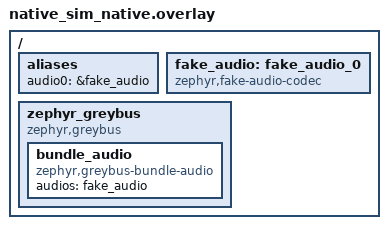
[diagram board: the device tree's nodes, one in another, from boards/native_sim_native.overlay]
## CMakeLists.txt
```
cmake_minimum_required(VERSION 3.20.0)
find_package(Zephyr REQUIRED HINTS $ENV{ZEPHYR_BASE})

set(DTS_ROOT ${CMAKE_CURRENT_SOURCE_DIR})
project(fake_audio_test)

get_filename_component(GB_ROOT ${CMAKE_CURRENT_SOURCE_DIR}/../../../.. ABSOLUTE)
target_include_directories(app PRIVATE 
  ${GB_ROOT}/drivers/audio
  ${GB_ROOT}/subsys/greybus
)

target_sources(app PRIVATE
  src/main.c 
  src/test_protocol.c
  ${GB_ROOT}/drivers/audio/fake_audio.c 
)
```

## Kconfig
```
source "Kconfig.zephyr"
rsource "../../../../drivers/audio/Kconfig"
```

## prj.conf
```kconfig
CONFIG_ZTEST=y
CONFIG_LOG=y
CONFIG_GREYBUS=y
CONFIG_GREYBUS_LOG_LEVEL_DBG=y 
CONFIG_GREYBUS_AUDIO=y
CONFIG_AUDIO=y
CONFIG_AUDIO_CODEC=y
CONFIG_FAKE_AUDIO=y
```

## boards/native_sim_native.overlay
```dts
/ {
    aliases {
        audio0 = &fake_audio;
    };

    fake_audio: fake_audio_0 {
        compatible = "zephyr,fake-audio-codec";
        status = "okay";
    };
    
    zephyr_greybus {
        compatible = "zephyr,greybus";
        status = "okay";
        
        bundle_audio: bundle_audio {
            compatible = "zephyr,greybus-bundle-audio";
            status = "okay";
            audios = <&fake_audio>; 
        };
    };
};
```

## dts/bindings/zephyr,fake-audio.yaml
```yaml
description: Fake Audio Codec Driver for Simulation
compatible: "zephyr,fake-audio-codec"
include: base.yaml
```

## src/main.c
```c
/*
 * Copyright (c) 2026 Pavithra C.P., BeagleBoard.org
 *
 * SPDX-License-Identifier: Apache-2.0
 */

#include <zephyr/ztest.h>
#include <zephyr/device.h>
#include <zephyr/audio/codec.h>
#include <zephyr/logging/log.h>
#include "fake_audio.h"

LOG_MODULE_REGISTER(audio_test, LOG_LEVEL_INF);

static const struct device *get_audio_dev(void)
{
    const struct device *dev = DEVICE_DT_GET(DT_NODELABEL(fake_audio));
    zassert_true(device_is_ready(dev), "The audio codec device is not ready!");
    return dev;
}

static void *audio_setup(void)
{
    get_audio_dev();
    LOG_INF("Audio Codec found and ready for testing.");
    return NULL;
}

ZTEST_SUITE(audio_tests, NULL, audio_setup, NULL, NULL, NULL);

ZTEST(audio_tests, test_codec_configure)
{
    const struct device *dev = get_audio_dev();
    struct audio_data *internal_state = dev->data;
    struct audio_codec_cfg cfg = {0};
    int ret;

    cfg.dai_type = AUDIO_DAI_TYPE_I2S;
    cfg.dai_cfg.pcm.samplerate = AUDIO_PCM_RATE_48K;

    ret = audio_codec_configure(dev, &cfg);
    zassert_equal(ret, 0, "audio_codec_configure failed");

    zassert_equal(internal_state->cfg.dai_type, AUDIO_DAI_TYPE_I2S, "DAI type not saved");
    zassert_equal(internal_state->cfg.dai_cfg.pcm.samplerate, AUDIO_PCM_RATE_48K, 
                  "Sample rate not saved");
}

ZTEST(audio_tests, test_output_volume)
{
    const struct device *dev = get_audio_dev();
    struct audio_data *internal_state = dev->data;
    audio_property_value_t val;
    int ret;

    val.vol = 75; /* Set volume to 75 -sample*/
    ret = audio_codec_set_property(dev, AUDIO_PROPERTY_OUTPUT_VOLUME, AUDIO_CHANNEL_ALL, val);
    
    zassert_equal(ret, 0, "Setting output volume failed");
    zassert_equal(internal_state->vol_out, 75, "Output volume state was not updated inside driver");
}

ZTEST(audio_tests, test_input_mute)
{
    const struct device *dev = get_audio_dev();
    struct audio_data *internal_state = dev->data;
    audio_property_value_t val;
    int ret;

    /*mute and unmute*/ 
    val.mute = true; 
    ret = audio_codec_set_property(dev, AUDIO_PROPERTY_INPUT_MUTE, AUDIO_CHANNEL_ALL, val);
    
    zassert_equal(ret, 0, "Setting input mute failed");
    zassert_true(internal_state->mute_in, "Input mute state was not updated to true");

    val.mute = false; 
    ret = audio_codec_set_property(dev, AUDIO_PROPERTY_INPUT_MUTE, AUDIO_CHANNEL_ALL, val);
    zassert_false(internal_state->mute_in, "Input mute state was not updated to false");
}

ZTEST(audio_tests, test_unsupported_property)
{
    const struct device *dev = get_audio_dev();
    audio_property_value_t val = { .vol = 0 };
    int ret;

    ret = audio_codec_set_property(dev, 9999, AUDIO_CHANNEL_ALL, val);
    zassert_equal(ret, -EINVAL, "Driver should return -EINVAL for unknown properties");
}

ZTEST(audio_tests, test_start_stop)
{
    const struct device *dev = get_audio_dev();
    struct audio_data *internal_state = dev->data;
    int ret;

    ret = audio_codec_start(dev, AUDIO_DAI_DIR_TXRX);
    zassert_equal(ret, 0, "Codec start failed");
    zassert_true(internal_state->is_started, "is_started flag not set to true");

    ret = audio_codec_stop(dev, AUDIO_DAI_DIR_TXRX);
    zassert_equal(ret, 0, "Codec stop failed");
    zassert_false(internal_state->is_started, "is_started flag not set to false");
}

ZTEST(audio_tests, test_null_api_safeguard)
{
    const struct device *dev = get_audio_dev();
    int ret;

    /* * We purposefully did not implement route_input in our fake driver. 
     * This test proves that the kernel safely catches it and returns -ENOSYS 
     * instead of causing a segmentation fault.
     */
    ret = audio_codec_route_input(dev, AUDIO_CHANNEL_ALL, 0);
    zassert_equal(ret, -ENOSYS, "Unimplemented API should return -ENOSYS");
}
```

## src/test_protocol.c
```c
/*
 * Copyright (c) 2026 Pavithra CP, BeagleBoard.org
 *
 * SPDX-License-Identifier: Apache-2.0
 */

#include "greybus/greybus_messages.h"
#include <zephyr/ztest.h>
#include <greybus/greybus.h>
#include <zephyr/kernel.h>
#include <zephyr/device.h>
#include <zephyr/sys/byteorder.h>
#include <zephyr/logging/log.h>
#include <zephyr/fff.h>
#include <greybus/greybus_protocols.h>
#include "greybus_audio.h"
#include "greybus_internal.h"

#define TEST_CPORT             4
#define TEST_CONTROL_ID_VOLUME 1

/*
 * Note- I have drv_data= {0} here to get rid
 * of the errors (declared but uninitialised). If that is not preferred,
 * I will initialise drv_data with memset(&drv_data, 0, sizeof(drv_data));
 */
ZTEST_SUITE(audio_protocol_tests, NULL, NULL, NULL, NULL, NULL);

ZTEST(audio_protocol_tests, test_audio_connection_lifecycle)
{
	struct gb_audio_driver_data drv_data = {0};

	gb_audio_driver.connected(&drv_data, TEST_CPORT);

	zassert_not_null(drv_data.dev, "Device pointer should be populated on connect");
	zassert_equal(drv_data.info.state, STATE_UNCONFIGURED,
		      "State should be STATE_UNCONFIGURED after connection");

	gb_audio_driver.disconnected(&drv_data);

	zassert_equal(drv_data.info.state, STATE_REMOVED,
		      "State should transition to STATE_REMOVED on disconnect");
}

ZTEST(audio_protocol_tests, test_audio_protocol_version)
{
	struct gb_audio_driver_data drv_data = {0};

	struct gb_message *msg = gb_message_request_alloc(0, GB_AUDIO_TYPE_PROTOCOL_VERSION, false);
	zassert_not_null(msg, "Failed to allocate message");

	msg->header.operation_id = 1;

	gb_audio_driver.connected(&drv_data, TEST_CPORT);

	gb_audio_driver.op_handler(&drv_data, msg, TEST_CPORT);

	zassert_equal(drv_data.info.state, STATE_UNCONFIGURED,
		      "Protocol Version request should not alter driver state");
}

ZTEST(audio_protocol_tests, test_audio_set_pcm_valid)
{
	struct gb_audio_driver_data drv_data = {0};

	gb_audio_driver.connected(&drv_data, TEST_CPORT);

	struct gb_message *msg = gb_message_request_alloc(sizeof(struct gb_audio_set_pcm_request),
							  GB_AUDIO_TYPE_SET_PCM, false);
	zassert_not_null(msg, "Failed to allocate SET_PCM message");

	struct gb_audio_set_pcm_request *req = (struct gb_audio_set_pcm_request *)msg->payload;
	req->rate = sys_cpu_to_le32(48000);
	req->channels = 2; // standard stereo audio- left and right
	req->sig_bits = 16;

	gb_audio_driver.op_handler(&drv_data, msg, TEST_CPORT);

	zassert_equal(drv_data.info.state, STATE_CONFIGURED,
		      "Driver should transition to STATE_CONFIGURED after valid PCM setup");
}

ZTEST(audio_protocol_tests, test_audio_set_control_volume)
{
	struct gb_audio_driver_data drv_data = {0};

	gb_audio_driver.connected(&drv_data, TEST_CPORT);

	struct gb_message *msg = gb_message_request_alloc(
		sizeof(struct gb_audio_set_control_request), GB_AUDIO_TYPE_SET_CONTROL, false);
	zassert_not_null(msg, "Failed to allocate SET_CONTROL message");

	struct gb_audio_set_control_request *req =
		(struct gb_audio_set_control_request *)msg->payload;
	req->control_id = TEST_CONTROL_ID_VOLUME;

	req->value.value.integer_value[0] = sys_cpu_to_le32(75); // arbitary value

	gb_audio_driver.op_handler(&drv_data, msg, TEST_CPORT);

	zassert_equal(drv_data.info.state, STATE_UNCONFIGURED,
		      "Driver state should remain stable after a control update");
}

ZTEST(audio_protocol_tests, test_audio_get_topology_size)
{
	struct gb_audio_driver_data drv_data = {0};

	gb_audio_driver.connected(&drv_data, TEST_CPORT);

	struct gb_message *msg =
		gb_message_request_alloc(0, GB_AUDIO_TYPE_GET_TOPOLOGY_SIZE, false);
	zassert_not_null(msg, "Failed to allocate GET_TOPOLOGY_SIZE message");

	gb_audio_driver.op_handler(&drv_data, msg, TEST_CPORT);

	zassert_equal(drv_data.info.state, STATE_UNCONFIGURED,
		      "Driver state should remain STATE_UNCONFIGURED after topology size query");
}

ZTEST(audio_protocol_tests, test_audio_get_topology)
{
	struct gb_audio_driver_data drv_data = {0};

	gb_audio_driver.connected(&drv_data, TEST_CPORT);

	struct gb_message *msg = gb_message_request_alloc(0, GB_AUDIO_TYPE_GET_TOPOLOGY, false);
	zassert_not_null(msg, "Failed to allocate GET_TOPOLOGY message");

	gb_audio_driver.op_handler(&drv_data, msg, TEST_CPORT);

	zassert_equal(drv_data.info.state, STATE_UNCONFIGURED,
		      "Driver state should remain STATE_UNCONFIGURED after topology query");
}

/*
 * Here the state is STATE_UNCONFIGURED by default upon connection
 * and it should remain unconfigured as it is an invalid command
 */
ZTEST(audio_protocol_tests, test_audio_activate_tx_unconfigured)
{
	struct gb_audio_driver_data drv_data = {0};
	gb_audio_driver.connected(&drv_data, TEST_CPORT);

	struct gb_message *msg = gb_message_request_alloc(0, GB_AUDIO_TYPE_ACTIVATE_TX, false);
	zassert_not_null(msg, "Failed to allocate ACTIVATE_TX message");

	gb_audio_driver.op_handler(&drv_data, msg, TEST_CPORT);

	zassert_equal(drv_data.info.state, STATE_UNCONFIGURED,
		      "State should not change on invalid TX activation");
}

ZTEST(audio_protocol_tests, test_audio_activate_tx_configured)
{
	struct gb_audio_driver_data drv_data = {0};
	gb_audio_driver.connected(&drv_data, TEST_CPORT);

	drv_data.info.state = STATE_CONFIGURED;

	struct gb_message *msg = gb_message_request_alloc(0, GB_AUDIO_TYPE_ACTIVATE_TX, false);
	zassert_not_null(msg, "Failed to allocate ACTIVATE_TX message");

	gb_audio_driver.op_handler(&drv_data, msg, TEST_CPORT);

	zassert_equal(drv_data.info.state, STATE_CONFIGURED,
		      "State should remain STATE_CONFIGURED after valid TX activation");
}

ZTEST(audio_protocol_tests, test_audio_send_data_unconfigured)
{
	struct gb_audio_driver_data drv_data = {0};
	gb_audio_driver.connected(&drv_data, TEST_CPORT);

	struct gb_message *msg = gb_message_request_alloc(
		sizeof(struct gb_audio_send_data_request) + 64, GB_AUDIO_TYPE_SEND_DATA, false);
	zassert_not_null(msg, "Failed to allocate SEND_DATA message");

	gb_audio_driver.op_handler(&drv_data, msg, TEST_CPORT);

	zassert_equal(drv_data.info.state, STATE_UNCONFIGURED,
		      "State should remain STATE_UNCONFIGURED after rejecting SEND_DATA");
}

ZTEST(audio_protocol_tests, test_audio_send_data_configured)
{
	struct gb_audio_driver_data drv_data = {0};
	gb_audio_driver.connected(&drv_data, TEST_CPORT);

	drv_data.info.state = STATE_CONFIGURED;

	struct gb_message *msg = gb_message_request_alloc(
		sizeof(struct gb_audio_send_data_request) + 128, GB_AUDIO_TYPE_SEND_DATA, false);
	zassert_not_null(msg, "Failed to allocate SEND_DATA message");

	gb_audio_driver.op_handler(&drv_data, msg, TEST_CPORT);

	zassert_equal(drv_data.info.state, STATE_CONFIGURED,
		      "State should remain STATE_CONFIGURED after successful SEND_DATA");
}

ZTEST(audio_protocol_tests, test_audio_deactivate_tx)
{
	struct gb_audio_driver_data drv_data = {0};
	gb_audio_driver.connected(&drv_data, TEST_CPORT);

	drv_data.info.state = STATE_CONFIGURED;

	struct gb_message *msg = gb_message_request_alloc(
		sizeof(struct gb_audio_deactivate_tx_request), GB_AUDIO_TYPE_DEACTIVATE_TX, false);
	zassert_not_null(msg, "Failed to allocate DEACTIVATE_TX message");

	gb_audio_driver.op_handler(&drv_data, msg, TEST_CPORT);

	zassert_equal(drv_data.info.state, STATE_CONFIGURED,
		      "State should remain STATE_CONFIGURED after DEACTIVATE_TX");
}

ZTEST(audio_protocol_tests, test_audio_deactivate_rx)
{
	struct gb_audio_driver_data drv_data = {0};
	gb_audio_driver.connected(&drv_data, TEST_CPORT);

	drv_data.info.state = STATE_CONFIGURED;

	struct gb_message *msg = gb_message_request_alloc(
		sizeof(struct gb_audio_deactivate_rx_request), GB_AUDIO_TYPE_DEACTIVATE_RX, false);
	zassert_not_null(msg, "Failed to allocate DEACTIVATE_RX message");

	gb_audio_driver.op_handler(&drv_data, msg, TEST_CPORT);

	zassert_equal(drv_data.info.state, STATE_CONFIGURED,
		      "State should remain STATE_CONFIGURED after DEACTIVATE_RX");
}

ZTEST(audio_protocol_tests, test_audio_jack_event)
{
	int ret;
	/* simulating a headphone insertion into widget ID 4 */
	ret = gb_audio_send_jack_event(TEST_CPORT, 4, GB_AUDIO_JACK_HEADPHONE,
				       GB_AUDIO_JACK_EVENT_INSERTION);

	zassert_equal(ret, -42, "Expected transport error -42 due to missing backend");
}

ZTEST(audio_protocol_tests, test_audio_button_event)
{
	int ret;
	/*Simulating pressing the ID 1 (play/pause) */
	ret = gb_audio_send_button_event(TEST_CPORT, 4, 1, GB_AUDIO_BUTTON_EVENT_PRESS);
	// since native_sim lacks a physical transport backend
	zassert_equal(ret, -42, "Expected transport error -42 due to missing backend");
}

ZTEST(audio_protocol_tests, test_audio_enable_widget)
{
	struct gb_audio_driver_data drv_data = {0};
	gb_audio_driver.connected(&drv_data, TEST_CPORT);

	struct gb_message *msg = gb_message_request_alloc(
		sizeof(struct gb_audio_enable_widget_request), GB_AUDIO_TYPE_ENABLE_WIDGET, false);
	zassert_not_null(msg, "Failed to allocate ENABLE_WIDGET message");

	gb_audio_driver.op_handler(&drv_data, msg, TEST_CPORT);
}

ZTEST(audio_protocol_tests, test_audio_disable_widget)
{
	struct gb_audio_driver_data drv_data = {0};
	gb_audio_driver.connected(&drv_data, TEST_CPORT);

	struct gb_message *msg =
		gb_message_request_alloc(sizeof(struct gb_audio_disable_widget_request),
					 GB_AUDIO_TYPE_DISABLE_WIDGET, false);
	zassert_not_null(msg, "Failed to allocate DISABLE_WIDGET message");

	gb_audio_driver.op_handler(&drv_data, msg, TEST_CPORT);
}
```
